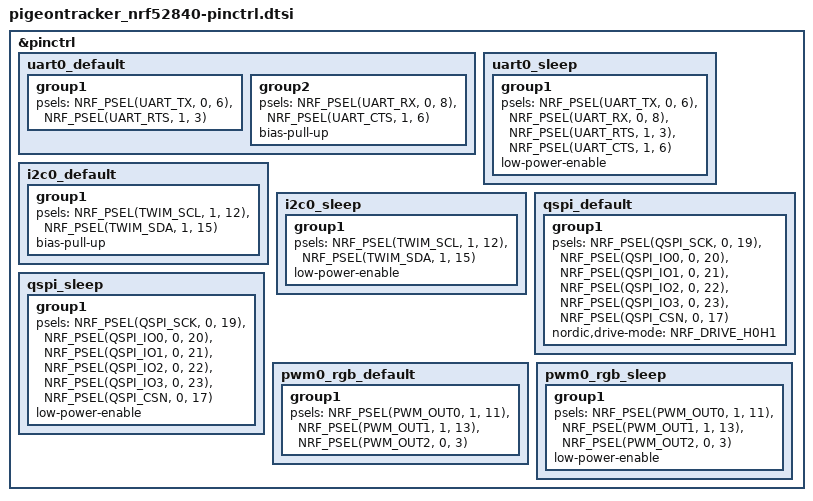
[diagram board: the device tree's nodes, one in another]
/*
 * PigeonTracker nRF52840 Pin Control Configuration
 *
 * Copyright (c) 2026 nRFModule
 * SPDX-License-Identifier: Apache-2.0
 *
 * Pins verified against the nRF_tracker_pigeon v1.0 netlist (2026-07-30),
 * identical to LiveTracker. No GPS UART: GNSS comes from the nRF9151 modem
 * over the shared serial-modem link.
 */

&pinctrl {
	/*
	 * Serial Modem UART (nRF52840 <-> nRF9151), HW flow control.
	 */
	uart0_default: uart0_default {
		group1 {
			psels = <NRF_PSEL(UART_TX, 0, 6)>,
			<NRF_PSEL(UART_RTS, 1, 3)>;
		};
		group2 {
			psels = <NRF_PSEL(UART_RX, 0, 8)>,
			<NRF_PSEL(UART_CTS, 1, 6)>;
			bias-pull-up;
		};
	};

	uart0_sleep: uart0_sleep {
		group1 {
			psels = <NRF_PSEL(UART_TX, 0, 6)>,
				<NRF_PSEL(UART_RX, 0, 8)>,
			<NRF_PSEL(UART_RTS, 1, 3)>,
			<NRF_PSEL(UART_CTS, 1, 6)>;
			low-power-enable;
		};
	};

	/*
	 * I2C0 for Sensors (LIS2DH12 Accelerometer, BMP390 Barometer)
	 */
	i2c0_default: i2c0_default {
		group1 {
			psels = <NRF_PSEL(TWIM_SCL, 1, 12)>,
				<NRF_PSEL(TWIM_SDA, 1, 15)>;
			bias-pull-up;
		};
	};

	i2c0_sleep: i2c0_sleep {
		group1 {
			psels = <NRF_PSEL(TWIM_SCL, 1, 12)>,
				<NRF_PSEL(TWIM_SDA, 1, 15)>;
			low-power-enable;
		};
	};

	/*
	 * QSPI for External Flash (MX25R6435F - 8MB)
	 */
	qspi_default: qspi_default {
		group1 {
			psels = <NRF_PSEL(QSPI_SCK, 0, 19)>,
				<NRF_PSEL(QSPI_IO0, 0, 20)>,
				<NRF_PSEL(QSPI_IO1, 0, 21)>,
				<NRF_PSEL(QSPI_IO2, 0, 22)>,
				<NRF_PSEL(QSPI_IO3, 0, 23)>,
				<NRF_PSEL(QSPI_CSN, 0, 17)>;
			nordic,drive-mode = <NRF_DRIVE_H0H1>;
		};
	};

	qspi_sleep: qspi_sleep {
		group1 {
			psels = <NRF_PSEL(QSPI_SCK, 0, 19)>,
				<NRF_PSEL(QSPI_IO0, 0, 20)>,
				<NRF_PSEL(QSPI_IO1, 0, 21)>,
				<NRF_PSEL(QSPI_IO2, 0, 22)>,
				<NRF_PSEL(QSPI_IO3, 0, 23)>,
				<NRF_PSEL(QSPI_CSN, 0, 17)>;
			low-power-enable;
		};
	};

	/*
	 * RGB status LED on PWM0 — common-anode, active-low.
	 */
	pwm0_rgb_default: pwm0_rgb_default {
		group1 {
			psels = <NRF_PSEL(PWM_OUT0, 1, 11)>,
				<NRF_PSEL(PWM_OUT1, 1, 13)>,
				<NRF_PSEL(PWM_OUT2, 0, 3)>;
		};
	};

	pwm0_rgb_sleep: pwm0_rgb_sleep {
		group1 {
			psels = <NRF_PSEL(PWM_OUT0, 1, 11)>,
				<NRF_PSEL(PWM_OUT1, 1, 13)>,
				<NRF_PSEL(PWM_OUT2, 0, 3)>;
			low-power-enable;
		};
	};
};
